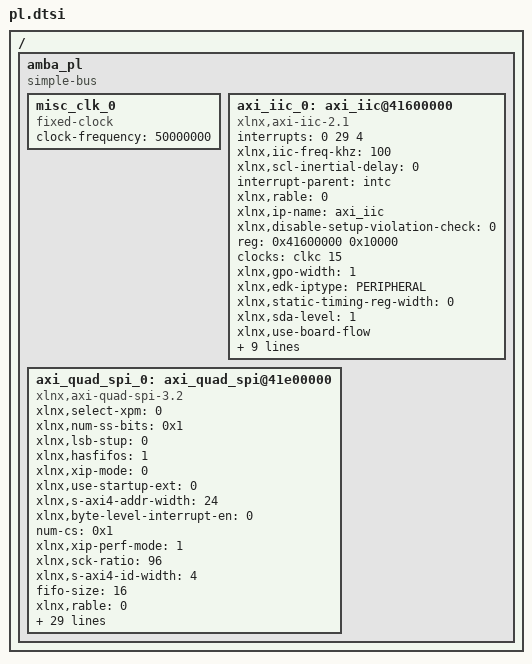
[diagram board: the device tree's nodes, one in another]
/ {
	amba_pl: amba_pl {
		ranges;
		compatible = "simple-bus";
		#address-cells = <1>;
		#size-cells = <1>;
		misc_clk_0: misc_clk_0 {
			compatible = "fixed-clock";
			clock-frequency = <50000000>;
			#clock-cells = <0>;
		};
		axi_iic_0: axi_iic@41600000 {
			interrupts = < 0 29 4 >;
			xlnx,iic-freq-khz = <100>;
			compatible = "xlnx,axi-iic-2.1" , "xlnx,xps-iic-2.00.a";
			xlnx,scl-inertial-delay = <0>;
			interrupt-parent = <&intc>;
			xlnx,rable = <0>;
			xlnx,ip-name = "axi_iic";
			xlnx,disable-setup-violation-check = <0>;
			reg = <0x41600000 0x10000>;
			clocks = <&clkc 15>;
			xlnx,gpo-width = <1>;
			xlnx,edk-iptype = "PERIPHERAL";
			xlnx,static-timing-reg-width = <0>;
			xlnx,sda-level = <1>;
			status = "okay";
			clock-names = "s_axi_aclk";
			xlnx,use-board-flow;
			xlnx,ten-bit-adr = <0>;
			xlnx,default-value = <0x00>;
			interrupt-names = "iic2intc_irpt";
			xlnx,timing-reg-width = <32>;
			xlnx,iic-board-interface = "respberry_i2c";
			xlnx,iic-freq = <100000>;
			xlnx,smbus-pmbus-host = <0>;
			xlnx,sda-inertial-delay = <0>;
			xlnx,name = "axi_iic_0";
			xlnx,axi-aclk-freq-mhz = <100>;
		};
		axi_quad_spi_0: axi_quad_spi@41e00000 {
			xlnx,select-xpm = <0>;
			xlnx,num-ss-bits = <0x1>;
			compatible = "xlnx,axi-quad-spi-3.2" , "xlnx,xps-spi-2.00.a";
			xlnx,lsb-stup = <0>;
			xlnx,hasfifos = <1>;
			xlnx,xip-mode = <0>;
			xlnx,use-startup-ext = <0>;
			xlnx,s-axi4-addr-width = <24>;
			xlnx,byte-level-interrupt-en = <0>;
			num-cs = <0x1>;
			xlnx,xip-perf-mode = <1>;
			xlnx,sck-ratio = <96>;
			xlnx,s-axi4-id-width = <4>;
			fifo-size = <16>;
			xlnx,rable = <0>;
			xlnx,multiples16 = <6>;
			xlnx,master-mode = <1>;
			xlnx,shared-startup = <0>;
			xlnx,ip-name = "axi_quad_spi";
			xlnx,qspi-board-interface = "spi";
			xlnx,new-seq-en = <1>;
			reg = <0x41e00000 0x10000>;
			xlnx,dual-quad-mode = <0>;
			bits-per-word = <8>;
			clocks = <&misc_clk_0>, <&clkc 15>;
			xlnx,num-transfer-bits = <8>;
			xlnx,spi-memory = <1>;
			xlnx,s-axi4-data-width = <32>;
			xlnx,edk-iptype = "PERIPHERAL";
			xlnx,slaveonly = <0>;
			xlnx,use-startup-int = <0>;
			xlnx,use-startup = <0>;
			xlnx,type-of-axi4-interface = <0>;
			xlnx,async-clk = <1>;
			xlnx,spi-mode = <0>;
			xlnx,sck-ratio1 = <1>;
			status = "okay";
			xlnx,fifo-depth = <16>;
			clock-names = "ext_spi_clk" , "s_axi_aclk";
			xlnx,uc-family = <0>;
			xlnx,spi-mem-addr-bits = <24>;
			xlnx,axi-interface = <0>;
			xlnx,Axi4-address = <0>;
			xlnx,sub-family = "zynq";
			xlnx,name = "axi_quad_spi_0";
			xlnx,fifo-included = <1>;
		};
	};
};
